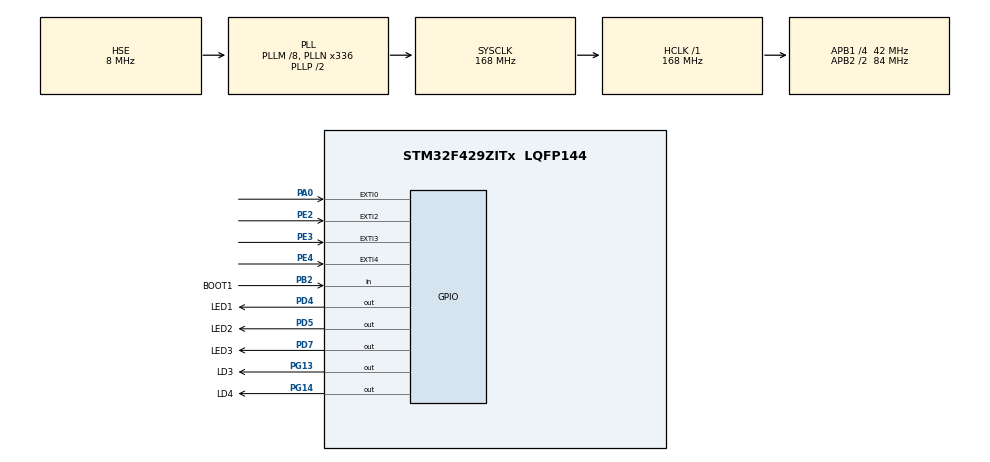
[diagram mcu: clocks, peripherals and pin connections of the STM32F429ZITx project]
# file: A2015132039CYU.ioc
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Mcu.Family=STM32F4
Mcu.Name=STM32F429ZITx
Mcu.Package=LQFP144
NVIC.EXTI0_IRQn=true\:0\:0\:false\:true\:true\:1\:true\:true
NVIC.EXTI2_IRQn=true\:0\:0\:false\:true\:true\:2\:true\:true
NVIC.EXTI3_IRQn=true\:0\:0\:false\:true\:true\:3\:true\:true
NVIC.EXTI4_IRQn=true\:0\:0\:false\:true\:true\:4\:true\:true
NVIC.PriorityGroup=NVIC_PRIORITYGROUP_4
NVIC.TIM3_IRQn=true\:0\:0\:false\:true\:true\:5\:true\:true
PA0/WKUP.Signal=GPXTI0
PA13.Mode=Serial_Wire
PA13.Signal=SYS_JTMS-SWDIO
PA14.Mode=Serial_Wire
PA14.Signal=SYS_JTCK-SWCLK
PB2/BOOT1.GPIO_Label=BOOT1
PB2/BOOT1.Signal=GPIO_Input
PD4.GPIO_Label=LED1
PD4.GPIO_Speed=GPIO_SPEED_FREQ_VERY_HIGH
PD4.Signal=GPIO_Output
PD5.GPIO_Label=LED2
PD5.GPIO_Speed=GPIO_SPEED_FREQ_VERY_HIGH
PD5.Signal=GPIO_Output
PD7.GPIO_Label=LED3
PD7.GPIO_Speed=GPIO_SPEED_FREQ_VERY_HIGH
PD7.Signal=GPIO_Output
PE2.GPIO_ModeDefaultEXTI=GPIO_MODE_IT_FALLING
PE2.Signal=GPXTI2
PE3.GPIO_ModeDefaultEXTI=GPIO_MODE_IT_FALLING
PE3.Signal=GPXTI3
PE4.GPIO_ModeDefaultEXTI=GPIO_MODE_IT_FALLING
PE4.Signal=GPXTI4
PG13.GPIO_Label=LD3
PG13.GPIO_Speed=GPIO_SPEED_FREQ_VERY_HIGH
PG13.Signal=GPIO_Output
PG14.GPIO_Label=LD4
PG14.GPIO_Speed=GPIO_SPEED_FREQ_VERY_HIGH
PG14.Signal=GPIO_Output
PH0/OSC_IN.Mode=HSE-External-Oscillator
PH0/OSC_IN.Signal=RCC_OSC_IN
PH1/OSC_OUT.Mode=HSE-External-Oscillator
PH1/OSC_OUT.Signal=RCC_OSC_OUT
ProjectManager.HeapSize=0x200
ProjectManager.StackSize=0x400
ProjectManager.TargetToolchain=EWARM V8
RCC.48MHZClocksFreq_Value=84000000
RCC.AHBFreq_Value=168000000
RCC.APB1CLKDivider=RCC_HCLK_DIV4
RCC.APB1Freq_Value=42000000
RCC.APB1TimFreq_Value=84000000
RCC.APB2CLKDivider=RCC_HCLK_DIV2
RCC.APB2Freq_Value=84000000
RCC.APB2TimFreq_Value=168000000
RCC.CortexFreq_Value=168000000
RCC.HCLKFreq_Value=168000000
RCC.HSE_VALUE=8000000
RCC.HSI_VALUE=16000000
RCC.LSE_VALUE=32768
RCC.PLLM=8
RCC.PLLN=336
RCC.PLLSourceVirtual=RCC_PLLSOURCE_HSE
RCC.SYSCLKFreq_VALUE=168000000
RCC.SYSCLKSource=RCC_SYSCLKSOURCE_PLLCLK
RCC.VCOOutputFreq_Value=336000000
TIM3.Period=5000-1
TIM3.Prescaler=8400-1
VP_TIM3_VS_ClockSourceINT.Mode=Internal
board=custom

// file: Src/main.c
/* USER CODE BEGIN Header */
/**
  ******************************************************************************
  * @file           : main.c
  * @brief          : Main program body
  ******************************************************************************
  * @attention
  *
  * <h2><center>&copy; Copyright (c) 2020 STMicroelectronics.
  * All rights reserved.</center></h2>
  *
  * This software component is licensed by ST under BSD 3-Clause license,
  * the "License"; You may not use this file except in compliance with the
  * License. You may obtain a copy of the License at:
  *                        opensource.org/licenses/BSD-3-Clause
  *
  ******************************************************************************
  */
/* USER CODE END Header */

#include "main.h"

TIM_HandleTypeDef htim3;

void SystemClock_Config(void);
static void MX_GPIO_Init(void);
static void MX_TIM3_Init(void);
static void MX_NVIC_Init(void);

int main(void)
{

  /* MCU Configuration--------------------------------------------------------*/

  /* Reset of all peripherals, Initializes the Flash interface and the Systick. */
  HAL_Init();

  /* Configure the system clock */
  SystemClock_Config();

  /* Initialize all configured peripherals */
  MX_GPIO_Init();
  MX_TIM3_Init();

  /* Initialize interrupts */
  MX_NVIC_Init();
  /* USER CODE BEGIN 2 */
HAL_TIM_Base_Start_IT(&htim3);
  /* USER CODE END 2 */

  /* Infinite loop */
  while (1)
  {

  }
}

void SystemClock_Config(void)
{
  RCC_OscInitTypeDef RCC_OscInitStruct = {0};
  RCC_ClkInitTypeDef RCC_ClkInitStruct = {0};

  /** Configure the main internal regulator output voltage
  */
  __HAL_RCC_PWR_CLK_ENABLE();
  __HAL_PWR_VOLTAGESCALING_CONFIG(PWR_REGULATOR_VOLTAGE_SCALE1);
  /** Initializes the CPU, AHB and APB busses clocks
  */
  RCC_OscInitStruct.OscillatorType = RCC_OSCILLATORTYPE_HSE;
  RCC_OscInitStruct.HSEState = RCC_HSE_ON;
  RCC_OscInitStruct.PLL.PLLState = RCC_PLL_ON;
  RCC_OscInitStruct.PLL.PLLSource = RCC_PLLSOURCE_HSE;
  RCC_OscInitStruct.PLL.PLLM = 8;
  RCC_OscInitStruct.PLL.PLLN = 336;
  RCC_OscInitStruct.PLL.PLLP = RCC_PLLP_DIV2;
  RCC_OscInitStruct.PLL.PLLQ = 4;
  if (HAL_RCC_OscConfig(&RCC_OscInitStruct) != HAL_OK)
  {
    Error_Handler();
  }
  /** Initializes the CPU, AHB and APB busses clocks
  */
  RCC_ClkInitStruct.ClockType = RCC_CLOCKTYPE_HCLK|RCC_CLOCKTYPE_SYSCLK
                              |RCC_CLOCKTYPE_PCLK1|RCC_CLOCKTYPE_PCLK2;
  RCC_ClkInitStruct.SYSCLKSource = RCC_SYSCLKSOURCE_PLLCLK;
  RCC_ClkInitStruct.AHBCLKDivider = RCC_SYSCLK_DIV1;
  RCC_ClkInitStruct.APB1CLKDivider = RCC_HCLK_DIV4;
  RCC_ClkInitStruct.APB2CLKDivider = RCC_HCLK_DIV2;

  if (HAL_RCC_ClockConfig(&RCC_ClkInitStruct, FLASH_LATENCY_5) != HAL_OK)
  {
    Error_Handler();
  }
}

/**
  * @brief NVIC Configuration.
  * @retval None
  */
static void MX_NVIC_Init(void)
{
  /* EXTI0_IRQn interrupt configuration */
  HAL_NVIC_SetPriority(EXTI0_IRQn, 0, 0);
  HAL_NVIC_EnableIRQ(EXTI0_IRQn);
  /* EXTI2_IRQn interrupt configuration */
  HAL_NVIC_SetPriority(EXTI2_IRQn, 0, 0);
  HAL_NVIC_EnableIRQ(EXTI2_IRQn);
  /* EXTI3_IRQn interrupt configuration */
  HAL_NVIC_SetPriority(EXTI3_IRQn, 0, 0);
  HAL_NVIC_EnableIRQ(EXTI3_IRQn);
  /* EXTI4_IRQn interrupt configuration */
  HAL_NVIC_SetPriority(EXTI4_IRQn, 0, 0);
  HAL_NVIC_EnableIRQ(EXTI4_IRQn);
  /* TIM3_IRQn interrupt configuration */
  HAL_NVIC_SetPriority(TIM3_IRQn, 0, 0);
  HAL_NVIC_EnableIRQ(TIM3_IRQn);
}

static void MX_TIM3_Init(void)
{

  TIM_ClockConfigTypeDef sClockSourceConfig = {0};
  TIM_MasterConfigTypeDef sMasterConfig = {0};

  htim3.Instance = TIM3;
  htim3.Init.Prescaler = 8400-1;
  htim3.Init.CounterMode = TIM_COUNTERMODE_UP;
  htim3.Init.Period = 5000-1;
  htim3.Init.ClockDivision = TIM_CLOCKDIVISION_DIV1;
  htim3.Init.AutoReloadPreload = TIM_AUTORELOAD_PRELOAD_DISABLE;
  if (HAL_TIM_Base_Init(&htim3) != HAL_OK)
  {
    Error_Handler();
  }
  sClockSourceConfig.ClockSource = TIM_CLOCKSOURCE_INTERNAL;
  if (HAL_TIM_ConfigClockSource(&htim3, &sClockSourceConfig) != HAL_OK)
  {
    Error_Handler();
  }
  sMasterConfig.MasterOutputTrigger = TIM_TRGO_RESET;
  sMasterConfig.MasterSlaveMode = TIM_MASTERSLAVEMODE_DISABLE;
  if (HAL_TIMEx_MasterConfigSynchronization(&htim3, &sMasterConfig) != HAL_OK)
  {
    Error_Handler();
  }

}

static void MX_GPIO_Init(void)
{
  GPIO_InitTypeDef GPIO_InitStruct = {0};

  /* GPIO Ports Clock Enable */
  __HAL_RCC_GPIOE_CLK_ENABLE();
  __HAL_RCC_GPIOH_CLK_ENABLE();
  __HAL_RCC_GPIOA_CLK_ENABLE();
  __HAL_RCC_GPIOB_CLK_ENABLE();
  __HAL_RCC_GPIOD_CLK_ENABLE();
  __HAL_RCC_GPIOG_CLK_ENABLE();

  /*Configure GPIO pin Output Level */
  HAL_GPIO_WritePin(GPIOD, LED1_Pin|LED2_Pin|LED3_Pin, GPIO_PIN_RESET);

  /*Configure GPIO pin Output Level */
  HAL_GPIO_WritePin(GPIOG, LD3_Pin|LD4_Pin, GPIO_PIN_RESET);

  /*Configure GPIO pins : PE2 PE3 PE4 */
  GPIO_InitStruct.Pin = GPIO_PIN_2|GPIO_PIN_3|GPIO_PIN_4;
  GPIO_InitStruct.Mode = GPIO_MODE_IT_FALLING;
  GPIO_InitStruct.Pull = GPIO_NOPULL;
  HAL_GPIO_Init(GPIOE, &GPIO_InitStruct);

  /*Configure GPIO pin : PA0 */
  GPIO_InitStruct.Pin = GPIO_PIN_0;
  GPIO_InitStruct.Mode = GPIO_MODE_IT_RISING;
  GPIO_InitStruct.Pull = GPIO_NOPULL;
  HAL_GPIO_Init(GPIOA, &GPIO_InitStruct);

  /*Configure GPIO pin : BOOT1_Pin */
  GPIO_InitStruct.Pin = BOOT1_Pin;
  GPIO_InitStruct.Mode = GPIO_MODE_INPUT;
  GPIO_InitStruct.Pull = GPIO_NOPULL;
  HAL_GPIO_Init(BOOT1_GPIO_Port, &GPIO_InitStruct);

  /*Configure GPIO pins : LED1_Pin LED2_Pin LED3_Pin */
  GPIO_InitStruct.Pin = LED1_Pin|LED2_Pin|LED3_Pin;
  GPIO_InitStruct.Mode = GPIO_MODE_OUTPUT_PP;
  GPIO_InitStruct.Pull = GPIO_NOPULL;
  GPIO_InitStruct.Speed = GPIO_SPEED_FREQ_VERY_HIGH;
  HAL_GPIO_Init(GPIOD, &GPIO_InitStruct);

  /*Configure GPIO pins : LD3_Pin LD4_Pin */
  GPIO_InitStruct.Pin = LD3_Pin|LD4_Pin;
  GPIO_InitStruct.Mode = GPIO_MODE_OUTPUT_PP;
  GPIO_InitStruct.Pull = GPIO_NOPULL;
  GPIO_InitStruct.Speed = GPIO_SPEED_FREQ_VERY_HIGH;
  HAL_GPIO_Init(GPIOG, &GPIO_InitStruct);

}

/* USER CODE BEGIN 4 */
void HAL_GPIO_EXTI_Callback(uint16_t GPIO_Pin)
  {
    if (GPIO_Pin== GPIO_PIN_0)
      HAL_GPIO_TogglePin(LED1_GPIO_Port, LED1_Pin | LED2_Pin | LED3_Pin);
    if (GPIO_Pin== GPIO_PIN_2)
      HAL_GPIO_TogglePin(LED1_GPIO_Port, LED1_Pin);
    if (GPIO_Pin== GPIO_PIN_3)
      HAL_GPIO_TogglePin(LED2_GPIO_Port, LED2_Pin);
    if (GPIO_Pin== GPIO_PIN_4)
      HAL_GPIO_TogglePin(LED3_GPIO_Port, LED3_Pin);
  }

void HAL_TIM_PeriodElapsedCallback(TIM_HandleTypeDef *htim)
{
  if( htim->Instance == TIM3)
  {
    HAL_GPIO_TogglePin(LD3_GPIO_Port,  LD3_Pin);
    HAL_GPIO_TogglePin(LD3_GPIO_Port,  LD4_Pin);
  }
}
/* USER CODE END 4 */

void Error_Handler(void)
{
}

/************************ (C) COPYRIGHT STMicroelectronics *****END OF FILE****/
